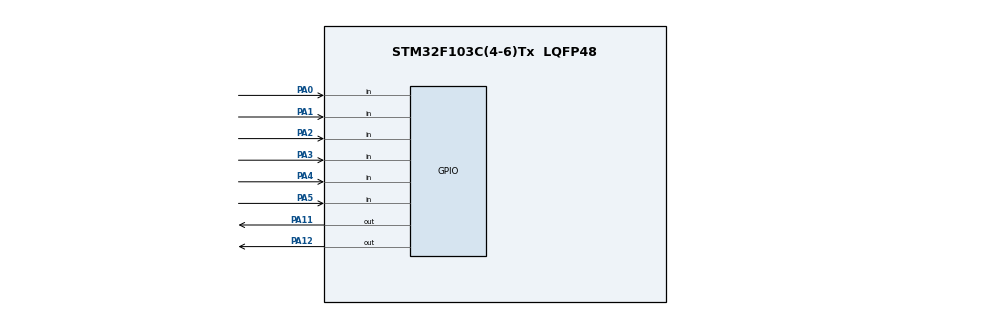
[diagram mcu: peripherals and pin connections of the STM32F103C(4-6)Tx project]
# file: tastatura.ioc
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Mcu.Family=STM32F1
Mcu.Name=STM32F103C(4-6)Tx
Mcu.Package=LQFP48
NVIC.PriorityGroup=NVIC_PRIORITYGROUP_4
PA0-WKUP.Signal=GPIO_Input
PA1.Signal=GPIO_Input
PA11.Signal=GPIO_Output
PA12.Signal=GPIO_Output
PA2.Signal=GPIO_Input
PA3.Signal=GPIO_Input
PA4.Signal=GPIO_Input
PA5.Signal=GPIO_Input
ProjectManager.HeapSize=0x200
ProjectManager.StackSize=0x400
ProjectManager.TargetToolchain=STM32CubeIDE
RCC.APB1Freq_Value=8000000
RCC.APB2Freq_Value=8000000
VP_SYS_VS_ND.Mode=No_Debug
board=custom

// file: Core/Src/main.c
/* USER CODE BEGIN Header */
/**
  ******************************************************************************
  * @file           : main.c
  * @brief          : Main program body
  ******************************************************************************
  * @attention
  *
  * <h2><center>&copy; Copyright (c) 2022 STMicroelectronics.
  * All rights reserved.</center></h2>
  *
  * This software component is licensed by ST under BSD 3-Clause license,
  * the "License"; You may not use this file except in compliance with the
  * License. You may obtain a copy of the License at:
  *                        opensource.org/licenses/BSD-3-Clause
  *
  ******************************************************************************
  */
/* USER CODE END Header */

#include "main.h"
#define r1 GPIO_PIN_0
#define r2 GPIO_PIN_1
#define r3 GPIO_PIN_2
#define c1 GPIO_PIN_3
#define c2 GPIO_PIN_4
#define c3 GPIO_PIN_5
#define green GPIO_PIN_11
#define red GPIO_PIN_12

void SystemClock_Config(void);
static void MX_GPIO_Init(void);

int main(void)
{

  /* MCU Configuration--------------------------------------------------------*/

  /* Reset of all peripherals, Initializes the Flash interface and the Systick. */
  HAL_Init();

  /* Configure the system clock */
  SystemClock_Config();

  /* Initialize all configured peripherals */
  MX_GPIO_Init();
  int prva=0,druga=0;
  /* Infinite loop */
  /* USER CODE BEGIN WHILE */
  HAL_GPIO_WritePin(GPIOA, red, GPIO_PIN_RESET);

  while (1)
  {

    /* USER CODE END WHILE */
	  HAL_GPIO_WritePin(GPIOA, r1, GPIO_PIN_SET);
	  if(HAL_GPIO_ReadPin(GPIOA, c1) == 0){
		  prva=druga;
		  druga=1;
	  }
	  if(HAL_GPIO_ReadPin(GPIOA, c2) == 0){
		  prva=druga;
		  		  druga=2;
	  	  }
	  if(HAL_GPIO_ReadPin(GPIOA, c3) == 0){
		  prva=druga;
		  		  druga=3;
	  	  }
	  HAL_GPIO_WritePin(GPIOA, r2, GPIO_PIN_SET);
	  if(HAL_GPIO_ReadPin(GPIOA, c1) == 0){
		  prva=druga;
		  		  druga=4;
	  	  }
	  if(HAL_GPIO_ReadPin(GPIOA, c2) == 0){
		  prva=druga;
		  		  druga=5;
	  	  }
	  if(HAL_GPIO_ReadPin(GPIOA, c3) == 0){
		  prva=druga;
		  		  druga=6;
	  	  }
	  HAL_GPIO_WritePin(GPIOA, r3, GPIO_PIN_SET);
	  if(HAL_GPIO_ReadPin(GPIOA, c1) == 0){
		  prva=druga;
		  		  druga=7;
	  	  }
	  if(HAL_GPIO_ReadPin(GPIOA, c2) == 0){
		  prva=druga;
		  		  druga=8;
	  	  }
	  if(HAL_GPIO_ReadPin(GPIOA, c3) == 0){
		  prva=druga;
		  		  druga=9;
	  	  }

	  	   if(prva==3 && druga==4) {

	  		 HAL_GPIO_WritePin(GPIOA, green, GPIO_PIN_RESET);
		     HAL_GPIO_WritePin(GPIOA, red, GPIO_PIN_SET);

	  	   }

  }
}

void SystemClock_Config(void)
{
  RCC_OscInitTypeDef RCC_OscInitStruct = {0};
  RCC_ClkInitTypeDef RCC_ClkInitStruct = {0};

  /** Initializes the CPU, AHB and APB busses clocks
  */
  RCC_OscInitStruct.OscillatorType = RCC_OSCILLATORTYPE_HSI;
  RCC_OscInitStruct.HSIState = RCC_HSI_ON;
  RCC_OscInitStruct.HSICalibrationValue = RCC_HSICALIBRATION_DEFAULT;
  RCC_OscInitStruct.PLL.PLLState = RCC_PLL_NONE;
  if (HAL_RCC_OscConfig(&RCC_OscInitStruct) != HAL_OK)
  {
    Error_Handler();
  }
  /** Initializes the CPU, AHB and APB busses clocks
  */
  RCC_ClkInitStruct.ClockType = RCC_CLOCKTYPE_HCLK|RCC_CLOCKTYPE_SYSCLK
                              |RCC_CLOCKTYPE_PCLK1|RCC_CLOCKTYPE_PCLK2;
  RCC_ClkInitStruct.SYSCLKSource = RCC_SYSCLKSOURCE_HSI;
  RCC_ClkInitStruct.AHBCLKDivider = RCC_SYSCLK_DIV1;
  RCC_ClkInitStruct.APB1CLKDivider = RCC_HCLK_DIV1;
  RCC_ClkInitStruct.APB2CLKDivider = RCC_HCLK_DIV1;

  if (HAL_RCC_ClockConfig(&RCC_ClkInitStruct, FLASH_LATENCY_0) != HAL_OK)
  {
    Error_Handler();
  }
}

static void MX_GPIO_Init(void)
{
  GPIO_InitTypeDef GPIO_InitStruct = {0};

  /* GPIO Ports Clock Enable */
  __HAL_RCC_GPIOA_CLK_ENABLE();

  /*Configure GPIO pin Output Level */
  HAL_GPIO_WritePin(GPIOA, GPIO_PIN_11|GPIO_PIN_12, GPIO_PIN_SET);

  /*Configure GPIO pins : PA0 PA1 PA2 PA3
                           PA4 PA5 */
  GPIO_InitStruct.Pin = GPIO_PIN_3
                          |GPIO_PIN_4|GPIO_PIN_5;
  GPIO_InitStruct.Mode = GPIO_MODE_INPUT;
  GPIO_InitStruct.Pull = GPIO_NOPULL;
  HAL_GPIO_Init(GPIOA, &GPIO_InitStruct);

  /*Configure GPIO pins : PA11 PA12 */
  GPIO_InitStruct.Pin = GPIO_PIN_0|GPIO_PIN_1|GPIO_PIN_2|GPIO_PIN_11|GPIO_PIN_12;
  GPIO_InitStruct.Mode = GPIO_MODE_OUTPUT_PP;
  GPIO_InitStruct.Pull = GPIO_NOPULL;
  GPIO_InitStruct.Speed = GPIO_SPEED_FREQ_LOW;
  HAL_GPIO_Init(GPIOA, &GPIO_InitStruct);

}

void Error_Handler(void)
{
}

/************************ (C) COPYRIGHT STMicroelectronics *****END OF FILE****/
